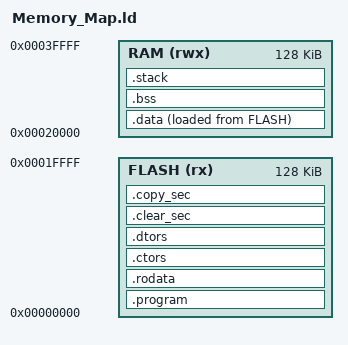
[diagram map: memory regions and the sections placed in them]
/******************************************************************************************
  Filename    : Memory_Map.ld
  
  Core        : ARM Cortex-M4
  
  SoC         : RP2350
    
  Author      : Chalandi Amine
 
  Owner       : Chalandi Amine
  
  Date        : 29.07.2025
  
  Description : Linker description file
  
******************************************************************************************/

/******************************************************************************************
 ELF Entrypoint
******************************************************************************************/
ENTRY(Startup_Init)

/******************************************************************************************
 Globals
******************************************************************************************/
__STACK_SIZE = 256;

/******************************************************************************************
 Memory configuration
******************************************************************************************/

MEMORY
{
  FLASH(rx)   : ORIGIN = 0x00000000, LENGTH = 128K
  RAM(rwx)    : ORIGIN = 0x00020000, LENGTH = 128K
}

/******************************************************************************************
 Sections definition
******************************************************************************************/
SECTIONS
{
  /* Program code */
  .program : ALIGN(4)
  {
    PROVIDE(__CODE_BASE_ADDRESS = .);
    PROVIDE(__INTVECT_BASE_ADDRESS = .);
    KEEP(*(.intvect))
    *(.text)
    *(.text*)
  } > FLASH

  /* Read-only data (.rodata) */
  .rodata : ALIGN(4)
  {
    PROVIDE(__RODATA_BASE_ADDRESS = .);
    *(.rodata)
  } > FLASH

 /* Section for constructors */
  .ctors : ALIGN(4)
  {
    PROVIDE(__CPPCTOR_LIST__ = .);
    KEEP (*(SORT(.ctors.*)))
    KEEP (*(.ctors))
    KEEP (*(SORT(.init_array.*)))
    KEEP (*(.init_array))
    LONG(-1) ;
    PROVIDE(__CPPCTOR_END__ = .);
    . = ALIGN(4);
  }  > FLASH


  /* Section for destructors */
  .dtors : ALIGN(4)
  {
    PROVIDE(__CPPDTOR_LIST__ = .);
    KEEP (*(SORT(.dtors.*)))
    KEEP (*(.dtors))
    KEEP (*(SORT(.fini_array.*)))
    KEEP (*(.fini_array))
    LONG(-1) ;
    PROVIDE(__CPPDTOR_END__ = .);
    . = ALIGN(4);
  } > FLASH

  /* Runtime clear table */
  .clear_sec : ALIGN(4)
  {
    PROVIDE(__RUNTIME_CLEAR_TABLE = .) ;
    LONG(0 + ADDR(.bss));   LONG(SIZEOF(.bss));
    LONG(-1);                 LONG(-1);
    . = ALIGN(4);
  } > FLASH

  /* Runtime copy table */
  .copy_sec : ALIGN(4)
  {
    PROVIDE(__RUNTIME_COPY_TABLE = .) ;
    LONG(LOADADDR(.data));  LONG(0 + ADDR(.data));  LONG(SIZEOF(.data));
    LONG(-1);                 LONG(-1);                  LONG(-1);
    . = ALIGN(4);
  } > FLASH

  /* The ROM-to-RAM initialized data section */
  .data :  ALIGN(4)
  {
    PROVIDE(__DATA_BASE_ADDRESS = .);
    *(.data)
    *(.data*)
  } > RAM  AT>FLASH

  /* The uninitialized (zero-cleared) bss section */
  .bss : ALIGN(4)
  {
    PROVIDE(__BSS_BASE_ADDRESS = .);
    *(.bss)
    *(.bss*)
  } > RAM

  /* stack definition */
  .stack :
  {
    . = ALIGN(MAX(__STACK_SIZE , .), 8);
    PROVIDE(__STACK_TOP = .) ;
  } > RAM

}
